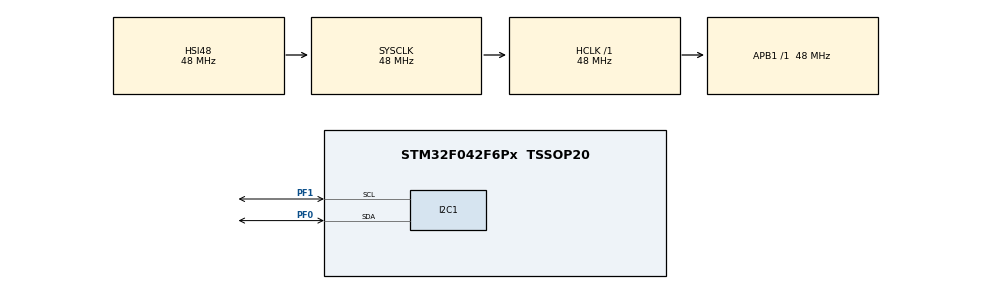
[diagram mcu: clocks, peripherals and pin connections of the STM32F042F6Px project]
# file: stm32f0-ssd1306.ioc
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Mcu.Family=STM32F0
Mcu.Name=STM32F042F6Px
Mcu.Package=TSSOP20
PF0-OSC_IN.Mode=I2C
PF0-OSC_IN.Signal=I2C1_SDA
PF1-OSC_OUT.Mode=I2C
PF1-OSC_OUT.Signal=I2C1_SCL
ProjectManager.HeapSize=0x100
ProjectManager.StackSize=0x100
ProjectManager.TargetToolchain=STM32CubeIDE
RCC.AHBFreq_Value=48000000
RCC.APB1Freq_Value=48000000
RCC.APB1TimFreq_Value=48000000
RCC.HCLKFreq_Value=48000000
RCC.SYSCLKFreq_VALUE=48000000
RCC.SYSCLKSource=RCC_SYSCLKSOURCE_HSI48
VP_SYS_VS_PINREMAP.Mode=PINREMAP
board=custom

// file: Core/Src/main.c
/* USER CODE BEGIN Header */
/**
  ******************************************************************************
  * @file           : main.c
  * @brief          : Main program body
  ******************************************************************************
  * @attention
  *
  * <h2><center>&copy; Copyright (c) 2020 STMicroelectronics.
  * All rights reserved.</center></h2>
  *
  * This software component is licensed by ST under BSD 3-Clause license,
  * the "License"; You may not use this file except in compliance with the
  * License. You may obtain a copy of the License at:
  *                        opensource.org/licenses/BSD-3-Clause
  *
  ******************************************************************************
  */
/* USER CODE END Header */

#include "main.h"

/* USER CODE BEGIN Includes */
#include "ssd1306.h"
#include "ssd1306_tests.h"
#include "stdio.h"
/* USER CODE END Includes */

I2C_HandleTypeDef hi2c1;

/* USER CODE BEGIN PV */
char dispBuffer[16];
/* USER CODE END PV */

void SystemClock_Config(void);
static void MX_GPIO_Init(void);
static void MX_I2C1_Init(void);

int main(void)
{

  /* MCU Configuration--------------------------------------------------------*/

  /* Reset of all peripherals, Initializes the Flash interface and the Systick. */
  HAL_Init();

  /* Configure the system clock */
  SystemClock_Config();

  /* Initialize all configured peripherals */
  MX_GPIO_Init();
  MX_I2C1_Init();
  /* USER CODE BEGIN 2 */

  ssd1306_TestAll();

//  ssd1306_SetCursor(2, 5);
//  ssd1306_WriteString("Freq:", Font_11x18, White);
//  ssd1306_UpdateScreen();
//  ssd1306_SetCursor(75, 40);
//  ssd1306_WriteString("Hz", Font_11x18, White);
//  ssd1306_UpdateScreen();
//
//  sprintf(dispBuffer, "%d", (int) fft_max_freq);
//  ssd1306_SetCursor(10, 40);
//  ssd1306_WriteString(dispBuffer, Font_11x18, White);
//  ssd1306_UpdateScreen();

  /* USER CODE END 2 */

  /* Infinite loop */
  while (1)
  {

  }
}

void SystemClock_Config(void)
{
  RCC_OscInitTypeDef RCC_OscInitStruct = {0};
  RCC_ClkInitTypeDef RCC_ClkInitStruct = {0};
  RCC_PeriphCLKInitTypeDef PeriphClkInit = {0};

  /** Initializes the CPU, AHB and APB busses clocks
  */
  RCC_OscInitStruct.OscillatorType = RCC_OSCILLATORTYPE_HSI|RCC_OSCILLATORTYPE_HSI48;
  RCC_OscInitStruct.HSIState = RCC_HSI_ON;
  RCC_OscInitStruct.HSI48State = RCC_HSI48_ON;
  RCC_OscInitStruct.HSICalibrationValue = RCC_HSICALIBRATION_DEFAULT;
  RCC_OscInitStruct.PLL.PLLState = RCC_PLL_NONE;
  if (HAL_RCC_OscConfig(&RCC_OscInitStruct) != HAL_OK)
  {
    Error_Handler();
  }
  /** Initializes the CPU, AHB and APB busses clocks
  */
  RCC_ClkInitStruct.ClockType = RCC_CLOCKTYPE_HCLK|RCC_CLOCKTYPE_SYSCLK
                              |RCC_CLOCKTYPE_PCLK1;
  RCC_ClkInitStruct.SYSCLKSource = RCC_SYSCLKSOURCE_HSI48;
  RCC_ClkInitStruct.AHBCLKDivider = RCC_SYSCLK_DIV1;
  RCC_ClkInitStruct.APB1CLKDivider = RCC_HCLK_DIV1;

  if (HAL_RCC_ClockConfig(&RCC_ClkInitStruct, FLASH_LATENCY_1) != HAL_OK)
  {
    Error_Handler();
  }
  PeriphClkInit.PeriphClockSelection = RCC_PERIPHCLK_I2C1;
  PeriphClkInit.I2c1ClockSelection = RCC_I2C1CLKSOURCE_HSI;
  if (HAL_RCCEx_PeriphCLKConfig(&PeriphClkInit) != HAL_OK)
  {
    Error_Handler();
  }
}

static void MX_I2C1_Init(void)
{

  hi2c1.Instance = I2C1;
  hi2c1.Init.Timing = 0x2000090E;
  hi2c1.Init.OwnAddress1 = 0;
  hi2c1.Init.AddressingMode = I2C_ADDRESSINGMODE_7BIT;
  hi2c1.Init.DualAddressMode = I2C_DUALADDRESS_DISABLE;
  hi2c1.Init.OwnAddress2 = 0;
  hi2c1.Init.OwnAddress2Masks = I2C_OA2_NOMASK;
  hi2c1.Init.GeneralCallMode = I2C_GENERALCALL_DISABLE;
  hi2c1.Init.NoStretchMode = I2C_NOSTRETCH_DISABLE;
  if (HAL_I2C_Init(&hi2c1) != HAL_OK)
  {
    Error_Handler();
  }
  /** Configure Analogue filter
  */
  if (HAL_I2CEx_ConfigAnalogFilter(&hi2c1, I2C_ANALOGFILTER_ENABLE) != HAL_OK)
  {
    Error_Handler();
  }
  /** Configure Digital filter
  */
  if (HAL_I2CEx_ConfigDigitalFilter(&hi2c1, 0) != HAL_OK)
  {
    Error_Handler();
  }

}

static void MX_GPIO_Init(void)
{

  /* GPIO Ports Clock Enable */
  __HAL_RCC_GPIOF_CLK_ENABLE();

}

void Error_Handler(void)
{
}

/************************ (C) COPYRIGHT STMicroelectronics *****END OF FILE****/
